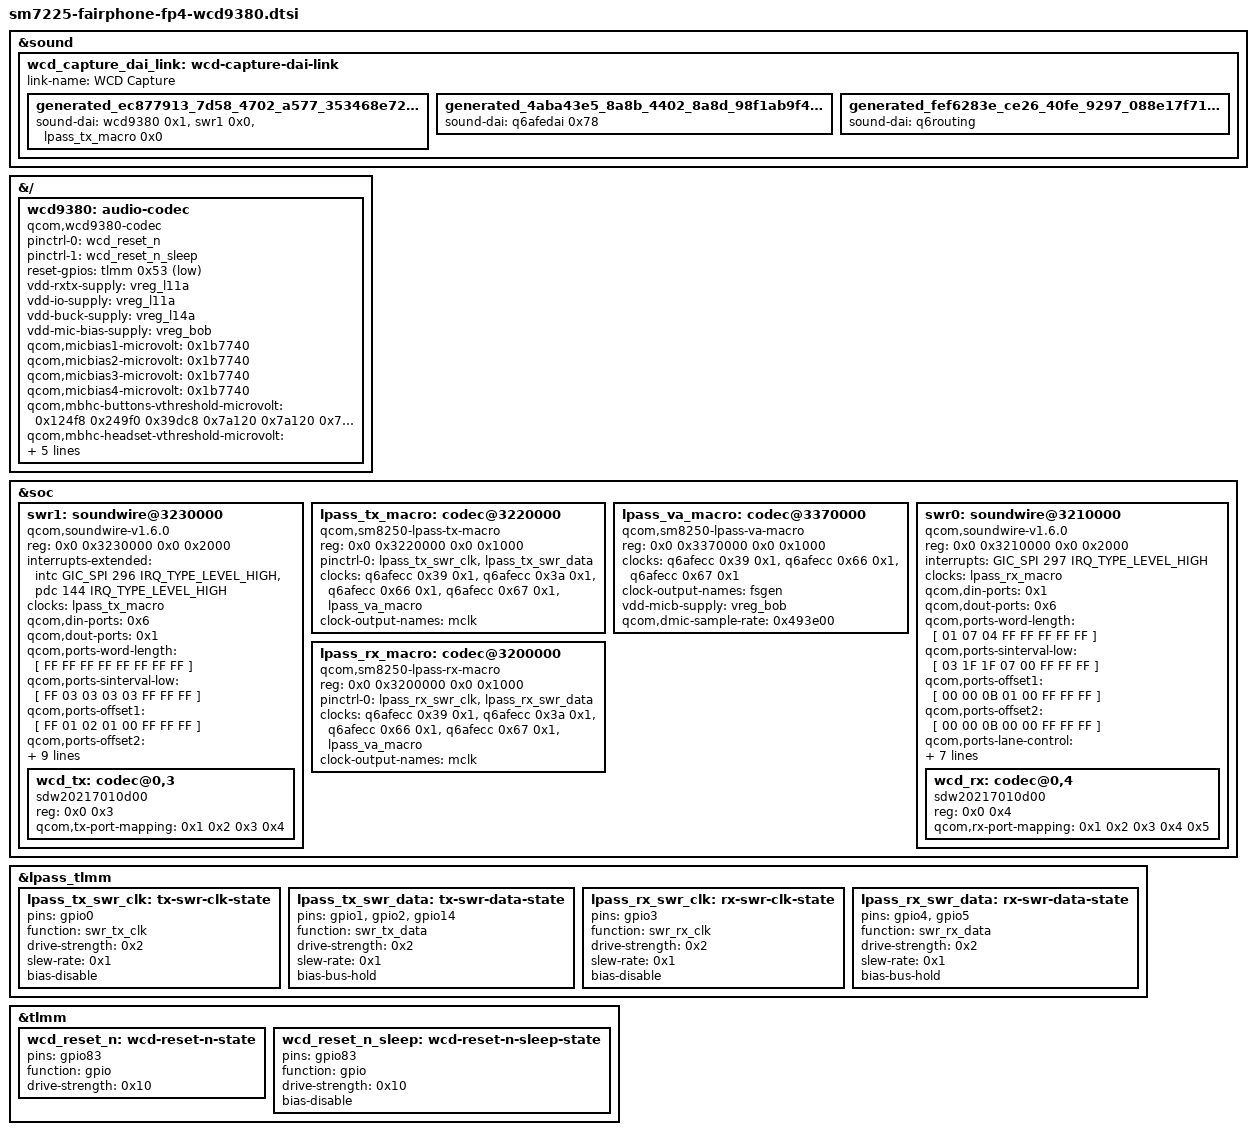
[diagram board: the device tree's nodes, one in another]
/* DTSI created with linux-devicetree-picker-AL Version 1.4 */

/*

https://github.com/sm8250-mainline/linux.git
commit f8442dd4bf0226c33aa78fa6db486ba8c70d66f8 (HEAD -> sm8250-7.2.y, tag: v7.2.2-sm8250, origin/sm8250-7.2.y)

./linux-devicetree-picker-AL.sh \
targetfile=../sm6350-mainline_linux/arch/arm64/boot/dts/qcom/sm7225-fairphone-fp4.dts \
includefolder=../sm6350-mainline_linux/include \
includefolder=../sm6350-mainline_linux/arch/arm64/boot/dts/include \
sourcefile=../sm8250-mainline_linux/arch/arm64/boot/dts/qcom/sm8250-fairphone-fp5.dts \
sourceincludefolder=../sm8250-mainline_linux/include \
sourceincludefolder=../sm8250-mainline_linux/arch/arm64/boot/dts/include \
outfilename=outfile.dtsi \
nodetoadd=wcd_capture_dai_link
*/

&sound {
   wcd_capture_dai_link:wcd-capture-dai-link {
      link-name = "WCD Capture";
   };
};

&wcd_capture_dai_link {
   generated_ec877913_7d58_4702_a577_353468e72dc9_codec:codec {
      sound-dai = < &wcd9380 0x1 >,
            < &swr1 0x0 >,
            < &lpass_tx_macro 0x0 >;
   };
};

&wcd_capture_dai_link {
   generated_4aba43e5_8a8b_4402_8a8d_98f1ab9f4160_cpu:cpu {
      sound-dai = < &q6afedai 0x78 >;
   };
};

&wcd_capture_dai_link {
   generated_fef6283e_ce26_40fe_9297_088e17f71bdb_platform:platform {
      sound-dai = < &q6routing >;
   };
};

&{/} {
   wcd9380:audio-codec {
      compatible = "qcom,wcd9380-codec";
      pinctrl-0 = < &wcd_reset_n >;
      pinctrl-1 = < &wcd_reset_n_sleep >;
      pinctrl-names = "default",
                "sleep";
      reset-gpios = < &tlmm 0x53 0x1 >;
      vdd-rxtx-supply = < &vreg_l11a >;
      vdd-io-supply = < &vreg_l11a >;
      vdd-buck-supply = < &vreg_l14a >;
      vdd-mic-bias-supply = < &vreg_bob >;
      qcom,micbias1-microvolt = < 0x1b7740 >;
      qcom,micbias2-microvolt = < 0x1b7740 >;
      qcom,micbias3-microvolt = < 0x1b7740 >;
      qcom,micbias4-microvolt = < 0x1b7740 >;
      qcom,mbhc-buttons-vthreshold-microvolt = < 0x124f8 0x249f0 0x39dc8 0x7a120 0x7a120 0x7a120 0x7a120 0x7a120 >;
      qcom,mbhc-headset-vthreshold-microvolt = < 0x19f0a0 >;
      qcom,mbhc-headphone-vthreshold-microvolt = < 0xc350 >;
      qcom,rx-device = < &wcd_rx >;
      qcom,tx-device = < &wcd_tx >;
      #sound-dai-cells = < 0x1 >;
      phandle = < 0x1a9 >;
   };
};

&soc {
   swr1:soundwire@3230000 {
      compatible = "qcom,soundwire-v1.6.0";
      reg = < 0x0 0x3230000 0x0 0x2000 >;
      interrupts-extended = 
            <&intc GIC_SPI 296 IRQ_TYPE_LEVEL_HIGH>, // From Android 15, lagoon-audio-overlay.dtsi
            <&pdc 144 IRQ_TYPE_LEVEL_HIGH>; // From Android 15, lagoon-audio-overlay.dtsi
      clocks = < &lpass_tx_macro >;
      clock-names = "iface";
      qcom,din-ports = < 0x6 >;
      qcom,dout-ports = < 0x1 >;
/*      resets = < &lpass_audiocc 0x1 >;
      reset-names = "swr_audio_cgcr";*/
      /* The following values come from Android kernel techpack/audio/asoc/kona-port-config.h */
      /* SWR_MSTR_PORT_LEN = 8 entries expected by driver */
      qcom,ports-word-length = [ FF FF FF FF FF FF FF FF ];
      qcom,ports-sinterval-low = [ FF 03 03 03 03 FF FF FF ];
      qcom,ports-offset1 = [ FF 01 02 01 00 FF FF FF ];
      qcom,ports-offset2 = [ FF 00 00 00 00 FF FF FF ];
      qcom,ports-lane-control = [ FF 00 00 00 00 FF FF FF ];
      qcom,ports-block-pack-mode = [ FF FF FF FF FF FF FF FF ];
      qcom,ports-hstart = [ FF FF FF FF FF FF FF FF ];
      qcom,ports-hstop = [ FF FF FF FF FF FF FF FF ];
      qcom,ports-block-group-count = [ FF FF FF FF FF FF FF FF ];
      #sound-dai-cells = < 0x1 >;
      #address-cells = < 0x2 >;
      #size-cells = < 0x0 >;
      status = "okay";
      phandle = < 0x1aa >;
   };
};

&swr1 {
   wcd_tx:codec@0,3 {
      compatible = "sdw20217010d00";
      reg = < 0x0 0x3 >;
      qcom,tx-port-mapping = < 0x1 0x2 0x3 0x4 >;
      phandle = < 0x1d2 >;
   };
};

&soc {
   lpass_tx_macro:codec@3220000 {
      reg = < 0x0 0x3220000 0x0 0x1000 >;
      pinctrl-names = "default";
      pinctrl-0 = < &lpass_tx_swr_clk >,
            < &lpass_tx_swr_data >;
      clocks = < &q6afecc 0x39 0x1 >,
         < &q6afecc 0x3a 0x1 >,
         < &q6afecc 0x66 0x1 >,
         < &q6afecc 0x67 0x1 >,
         < &lpass_va_macro >;
      clock-names = "mclk",
              "npl",
              "macro",
              "dcodec",
              "fsgen";
      clock-output-names = "mclk";
      #clock-cells = < 0x0 >;
      #sound-dai-cells = < 0x1 >;
      status = "okay";
      compatible = "qcom,sm8250-lpass-tx-macro";
      phandle = < 0xf2 >;
   };
};

&lpass_tlmm {
   lpass_tx_swr_clk:tx-swr-clk-state {
      pins = "gpio0";
      function = "swr_tx_clk";
      drive-strength = < 0x2 >;
      slew-rate = < 0x1 >;
      bias-disable;
      phandle = < 0xef >;
   };
};

&lpass_tlmm {
   lpass_tx_swr_data:tx-swr-data-state {
      pins = "gpio1",
       "gpio2",
       "gpio14";
      function = "swr_tx_data";
      drive-strength = < 0x2 >;
      slew-rate = < 0x1 >;
      bias-bus-hold;
      phandle = < 0xf0 >;
   };
};

&soc {
   lpass_va_macro:codec@3370000 {
      compatible = "qcom,sm8250-lpass-va-macro";
      reg = < 0x0 0x3370000 0x0 0x1000 >;
      clocks = < &q6afecc 0x39 0x1 >,
         < &q6afecc 0x66 0x1 >,
         < &q6afecc 0x67 0x1 >;
      clock-names = "mclk",
              "macro",
              "dcodec";
      clock-output-names = "fsgen";
      #clock-cells = < 0x0 >;
      #sound-dai-cells = < 0x1 >;
      vdd-micb-supply = < &vreg_bob >;
      qcom,dmic-sample-rate = < 0x493e00 >;
      status = "okay";
      phandle = < 0xec >;
   };
};

&tlmm {
   wcd_reset_n:wcd-reset-n-state {
      pins = "gpio83";
      function = "gpio";
      drive-strength = < 0x10 >;
      phandle = < 0x1ce >;
   };
};

&tlmm {
   wcd_reset_n_sleep:wcd-reset-n-sleep-state {
      pins = "gpio83";
      function = "gpio";
      drive-strength = < 0x10 >;
      bias-disable;
      phandle = < 0x1cf >;
   };
};

&soc {
   swr0:soundwire@3210000 {
      compatible = "qcom,soundwire-v1.6.0";
      reg = < 0x0 0x3210000 0x0 0x2000 >;
      interrupts = <GIC_SPI 297 IRQ_TYPE_LEVEL_HIGH>; // From Android 15, lagoon-audio-overlay.dtsi
      interrupt-names = "swr_master_irq"; // From Android 15, lagoon-audio-overlay.dtsi
      clocks = < &lpass_rx_macro >;
      clock-names = "iface";
      qcom,din-ports = < 0x1 >;
      qcom,dout-ports = < 0x6 >;
/*      resets = < &lpass_audiocc 0x0 >;
      reset-names = "swr_audio_cgcr";*/
      /* The following values come from Android kernel techpack/audio/asoc/kona-port-config.h */
      /* SWR_MSTR_PORT_LEN = 8 entries expected by driver */
      qcom,ports-word-length = [ 01 07 04 FF FF FF FF FF ];
      qcom,ports-sinterval-low = [ 03 1F 1F 07 00 FF FF FF ];
      qcom,ports-offset1 = [ 00 00 0B 01 00 FF FF FF ];
      qcom,ports-offset2 = [ 00 00 0B 00 00 FF FF FF ];
      qcom,ports-lane-control = [ 01 00 00 00 00 FF FF FF ];
      qcom,ports-block-pack-mode = [ FF 00 01 FF FF FF FF FF ];
      qcom,ports-hstart = [ FF 03 FF FF FF FF FF FF ];
      qcom,ports-hstop = [ FF 06 FF FF FF FF FF FF ];
      qcom,ports-block-group-count = [ FF FF FF FF 00 FF FF FF ];
      #sound-dai-cells = < 0x1 >;
      #address-cells = < 0x2 >;
      #size-cells = < 0x0 >;
      status = "okay";
   };
};

&swr0 {
   wcd_rx:codec@0,4 {
      compatible = "sdw20217010d00";
      reg = < 0x0 0x4 >;
      qcom,rx-port-mapping = < 0x1 0x2 0x3 0x4 0x5 >;
      phandle = < 0x1d1 >;
   };
};

&soc {
   lpass_rx_macro:codec@3200000 {
      compatible = "qcom,sm8250-lpass-rx-macro";
      reg = < 0x0 0x3200000 0x0 0x1000 >;
      pinctrl-names = "default";
      pinctrl-0 = < &lpass_rx_swr_clk >,
            < &lpass_rx_swr_data >;
      clocks = < &q6afecc 0x39 0x1 >,
         < &q6afecc 0x3a 0x1 >,
         < &q6afecc 0x66 0x1 >,
         < &q6afecc 0x67 0x1 >,
         < &lpass_va_macro >;
      clock-names = "mclk",
              "npl",
              "macro",
              "dcodec",
              "fsgen";
      clock-output-names = "mclk";
      #clock-cells = < 0x0 >;
      #sound-dai-cells = < 0x1 >;
      status = "okay";
      phandle = < 0xed >;
   };
};

&lpass_tlmm {
   lpass_rx_swr_clk:rx-swr-clk-state {
      pins = "gpio3";
      function = "swr_rx_clk";
      drive-strength = < 0x2 >;
      slew-rate = < 0x1 >;
      bias-disable;
      phandle = < 0xe9 >;
   };
};

&lpass_tlmm {
   lpass_rx_swr_data:rx-swr-data-state {
      pins = "gpio4",
       "gpio5";
      function = "swr_rx_data";
      drive-strength = < 0x2 >;
      slew-rate = < 0x1 >;
      bias-bus-hold;
      phandle = < 0xea >;
   };
};

